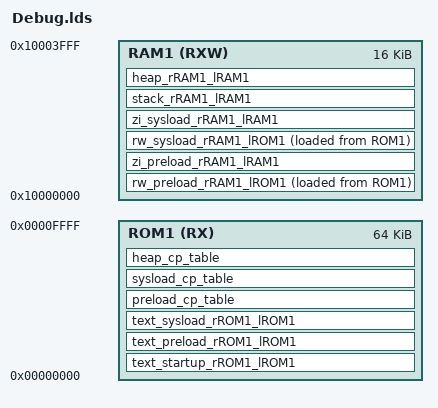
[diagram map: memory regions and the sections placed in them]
/* ld Linker Script - (Debug/Release) */
/* Auto generated by DJYOS lds Editor */
/* Sat Sep 07 15:31:13 CST 2013 */

MEMORY
{
	ROM1(RX)		: org = 0x00000000, len = 64k
	RAM1(RXW)		: org = 0x10000000, len = 16k
}

SECTIONS
{
	
	. = ALIGN(0x08);
	text_startup_rROM1_lROM1 :
	{
		KEEP(* (.isr_vector .isr_vector.*))
		./src/OS_code/bsp/arch/core/exceptions.o (.text .text.* .rodata .rodata.*)
		./src/OS_code/bsp/arch/startup/*.o (.text .text.* .rodata .rodata.*)
		./src/OS_code/loader/si/pre_loader.o (.text .text.* .rodata .rodata.*)
	}>ROM1 
	
	. = ALIGN(0x08);
	text_preload_rROM1_lROM1 :
	{
		./src/OS_code/loader/si/loader.o (.text .text.* .rodata .rodata.*)
		./src/OS_code/bsp/arch/core/int_hard.o (.text .text.* .rodata .rodata.*)
		./src/OS_code/djyos/int/int.o (.text .text.* .rodata .rodata.*)
		./src/OS_code/bsp/arch/core/ints.o (.text .text.* .rodata .rodata.*)
		./src/user/critical/*.o (.text .text.* .rodata .rodata.*)
		./src/OS_code/bsp/cpu_peripheral/src/gpio.o (.text .text.* .rodata .rodata.*)
	}>ROM1 
	
	. = ALIGN(0x08);
	rw_preload_rRAM1_lROM1 :
	{
		KEEP(* (.table.exceptions .table.exceptions.*))
		KEEP(* (.table.vectors .table.vectors.*))
		./src/OS_code/loader/si/loader.o (.data .data.*)
		./src/OS_code/bsp/arch/core/int_hard.o (.data .data.*)
		./src/OS_code/djyos/int/int.o (.data .data.*)
		./src/OS_code/bsp/arch/core/ints.o (.data .data.*)
		./src/user/critical/*.o (.data .data.*)
		./src/OS_code/bsp/cpu_peripheral/src/gpio.o (.data .data.*)
	}>RAM1 AT>ROM1
	
	. = ALIGN(0x08);
	zi_preload_rRAM1_lRAM1 (NOLOAD) :
	{
		./src/OS_code/loader/si/loader.o (.bss .bss.* COMMON)
		./src/OS_code/bsp/arch/core/int_hard.o (.bss .bss.* COMMON)
		./src/OS_code/djyos/int/int.o (.bss .bss.* COMMON)
		./src/OS_code/bsp/arch/core/ints.o (.bss .bss.* COMMON)
		./src/user/critical/*.o (.bss .bss.* COMMON)
		./src/OS_code/bsp/cpu_peripheral/src/gpio.o (.bss .bss.* COMMON)
	}>RAM1 
	
	. = ALIGN(0x08);
	text_sysload_rROM1_lROM1 :
	{
		* (.text .text.* .rodata .rodata.*)
	}>ROM1 
	
	. = ALIGN(0x08);
	rw_sysload_rRAM1_lROM1 :
	{
		* (.data .data.*)
	}>RAM1 AT>ROM1
	
	. = ALIGN(0x08);
	zi_sysload_rRAM1_lRAM1 (NOLOAD) :
	{
		* (.bss .bss.* COMMON)
	}>RAM1 
	
	. = ALIGN(0x08);
	preload_cp_table :
	{
		preload_copy_table = .;
		LONG(16)
		LONG(3)
		
		LONG(LOADADDR(text_preload_rROM1_lROM1))
		LONG(ADDR(text_preload_rROM1_lROM1))
		LONG(SIZEOF(text_preload_rROM1_lROM1))
		LONG(1)
		
		LONG(LOADADDR(rw_preload_rRAM1_lROM1))
		LONG(ADDR(rw_preload_rRAM1_lROM1))
		LONG(SIZEOF(rw_preload_rRAM1_lROM1))
		LONG(1)
		
		LONG(LOADADDR(zi_preload_rRAM1_lRAM1))
		LONG(ADDR(zi_preload_rRAM1_lRAM1))
		LONG(SIZEOF(zi_preload_rRAM1_lRAM1))
		LONG(0)
	}>ROM1 
	
	. = ALIGN(0x08);
	sysload_cp_table :
	{
		sysload_copy_table = .;
		LONG(16)
		LONG(3)
		
		LONG(LOADADDR(text_sysload_rROM1_lROM1))
		LONG(ADDR(text_sysload_rROM1_lROM1))
		LONG(SIZEOF(text_sysload_rROM1_lROM1))
		LONG(1)
		
		LONG(LOADADDR(rw_sysload_rRAM1_lROM1))
		LONG(ADDR(rw_sysload_rRAM1_lROM1))
		LONG(SIZEOF(rw_sysload_rRAM1_lROM1))
		LONG(1)
		
		LONG(LOADADDR(zi_sysload_rRAM1_lRAM1))
		LONG(ADDR(zi_sysload_rRAM1_lRAM1))
		LONG(SIZEOF(zi_sysload_rRAM1_lRAM1))
		LONG(0)
	}>ROM1 
	
	. = ALIGN(0x08);
	stack_rRAM1_lRAM1 (NOLOAD) :
	{
		msp_bottom = .;
		KEEP(* (.stack.msp .stack.msp.*))
		msp_top = ALIGN(0x08);
		
	}>RAM1 
	
	. = ALIGN(0x08);
	heap_rRAM1_lRAM1 (NOLOAD) :
	{
		sys_heap_bottom = .;
	}>RAM1 
	sys_heap_top = 0x10000000+16k;
	
	. = ALIGN(0x08);
	heap_cp_table :
	{
		heap_copy_table = .;
		LONG(12)
		LONG(1)
		
		sys_heap_bottom_cnt = .;
		LONG(sys_heap_bottom)
		sys_heap_top_cnt = .;
		LONG(sys_heap_top)
	}>ROM1 
}
/**** The End ****/
